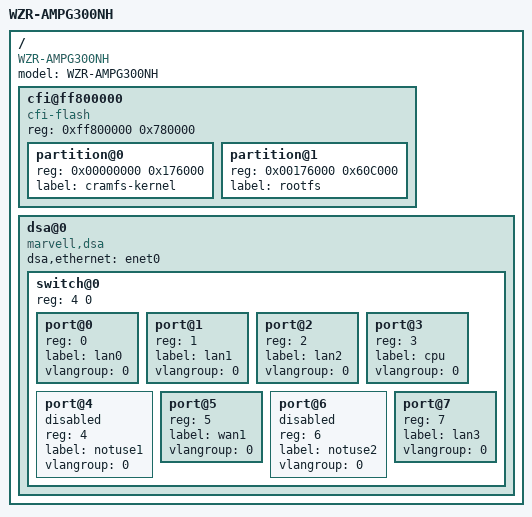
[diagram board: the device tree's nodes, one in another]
/*
 * Copyright (c) 2010 The FreeBSD Foundation
 * All rights reserved.
 *
 * Copyright (c) 2017 Hiroki Mori
 *
 * Redistribution and use in source and binary forms, with or without
 * modification, are permitted provided that the following conditions
 * are met:
 * 1. Redistributions of source code must retain the above copyright
 *    notice, this list of conditions and the following disclaimer.
 * 2. Redistributions in binary form must reproduce the above copyright
 *    notice, this list of conditions and the following disclaimer in the
 *    documentation and/or other materials provided with the distribution.
 *
 * THIS SOFTWARE IS PROVIDED BY THE AUTHOR AND CONTRIBUTORS ``AS IS'' AND
 * ANY EXPRESS OR IMPLIED WARRANTIES, INCLUDING, BUT NOT LIMITED TO, THE
 * IMPLIED WARRANTIES OF MERCHANTABILITY AND FITNESS FOR A PARTICULAR PURPOSE
 * ARE DISCLAIMED. IN NO EVENT SHALL THE AUTHOR OR CONTRIBUTORS BE LIABLE
 * FOR ANY DIRECT, INDIRECT, INCIDENTAL, SPECIAL, EXEMPLARY, OR CONSEQUENTIAL
 * DAMAGES (INCLUDING, BUT NOT LIMITED TO, PROCUREMENT OF SUBSTITUTE GOODS
 * OR SERVICES; LOSS OF USE, DATA, OR PROFITS; OR BUSINESS INTERRUPTION)
 * HOWEVER CAUSED AND ON ANY THEORY OF LIABILITY, WHETHER IN CONTRACT, STRICT
 * LIABILITY, OR TORT (INCLUDING NEGLIGENCE OR OTHERWISE) ARISING IN ANY WAY
 * OUT OF THE USE OF THIS SOFTWARE, EVEN IF ADVISED OF THE POSSIBILITY OF
 * SUCH DAMAGE.
 *
 * WZR-AMPG300NH Device Tree Source.
 *
 * $FreeBSD$
 */

/dts-v1/;

#include "db88f5181.dtsi"

/ {
	compatible = "WZR-AMPG300NH", "marvell,db88f5181";
	model = "WZR-AMPG300NH";

	cfi@ff800000 {
		#address-cells = <1>;
		#size-cells = <1>;
		compatible = "cfi-flash";
		reg = <0xff800000 0x780000>;		// 8M at 0xff800000
		partition@0 {
			reg = <0x00000000 0x176000>;
			label = "cramfs-kernel";
		};
		partition@1 {
			reg = <0x00176000 0x60C000>;
			label = "rootfs";
		};
#if 0
		partition@2 {
			reg = <0x00780000 0x2000>;
			label = "user_property";
		};
		partition@3 {
			reg = <0x007a0000 0x2000>;
			label = "uboot_environ";
		};
		partition@4 {
			reg = <0x007c0000 0x4000>;
			label = "uboot";
		};
		partition@5 {
			reg = <0x00010000 0x003c0000>;
			label = "upgrade";
		};
#endif
	};

	// Marvell 88E6131
	dsa@0 {
		compatible = "marvell,dsa" , "mrvl,sw";
		dsa,ethernet = <&enet0>;
//		dsa,mii-bus = <&mdio>;
                switch@0 {
                        #address-cells = <1>;
                        #size-cells = <0>;
                        reg = <4 0>;

                        port@0 {
                                reg = <0>;
                                label = "lan0";
                                vlangroup = <0>;
                        };

                        port@1 {
                                reg = <1>;
                                label = "lan1";
                                vlangroup = <0>;
                        };

                        port@2 {
                                reg = <2>;
                                label = "lan2";
                                vlangroup = <0>;
                        };

                       port@3 {
                                reg = <3>;
                                label = "cpu";
                                vlangroup = <0>;
                        };

                        port@4 {
                                reg = <4>;
                                label = "notuse1";
                                vlangroup = <0>;
				status = "disabled";
                        };

			// Ex Trans
                        port@5 {
                                reg = <5>;
                                label = "wan1";
                                vlangroup = <0>;
                        };

                        port@6 {
                                reg = <6>;
                                label = "notuse2";
                                vlangroup = <0>;
				status = "disabled";
                        };

			// Ex Trans
                        port@7 {
                                reg = <7>;
                                label = "lan3";
                                vlangroup = <0>;
                        };

		};
	};

};
